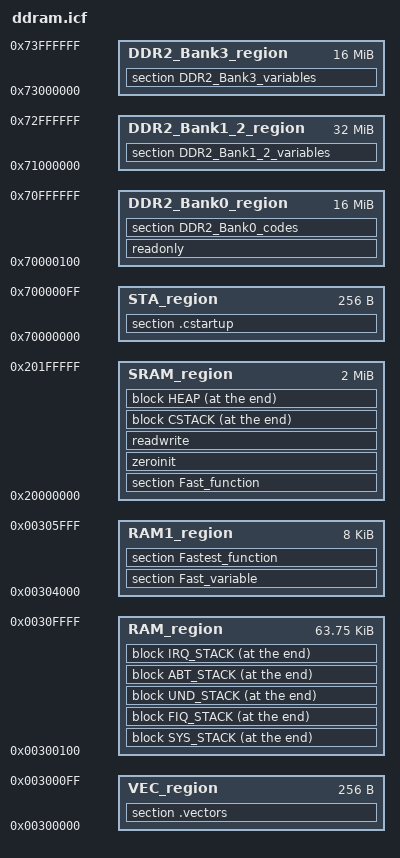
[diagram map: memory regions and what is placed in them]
/*###ICF### Section handled by ICF editor, don't touch! ****/
/*-Editor annotation file-*/
/* IcfEditorFile="$TOOLKIT_DIR$\config\ide\IcfEditor\a_v1_0.xml" */
/*-Memory Regions-*/
define symbol __ICFEDIT_region_SRAM_start__ = 0x20000000;
define symbol __ICFEDIT_region_SRAM_end__   = 0x201FFFFF;

define symbol __ICFEDIT_region_DDR2_Bank0_start__ = 0x70000000;
define symbol __ICFEDIT_region_DDR2_Bank0_end__   = 0x70FFFFFF;
define symbol __ICFEDIT_region_DDR2_Bank1_2_start__ = 0x71000000;
define symbol __ICFEDIT_region_DDR2_Bank1_2_end__   = 0x72FFFFFF;
define symbol __ICFEDIT_region_DDR2_Bank3_start__ = 0x73000000;
define symbol __ICFEDIT_region_DDR2_Bank3_end__   = 0x73FFFFFF;

define symbol __ICFEDIT_region_RAM1_start__   = 0x304000;
define symbol __ICFEDIT_region_RAM1_end__     = 0x305FFF;
define symbol __ICFEDIT_region_IRAM_start__   = 0x300000;
define symbol __ICFEDIT_region_IRAM_end__     = 0x30FFFF;

/*-Sizes-*/
define symbol __ICFEDIT_size_startup__  = 0x100;
define symbol __ICFEDIT_size_vectors__  = 0x100;
define symbol __ICFEDIT_size_cstack__   = 0x2000;
define symbol __ICFEDIT_size_sysstack__ = 0x60;
define symbol __ICFEDIT_size_irqstack__ = 0x60;
define symbol __ICFEDIT_size_fiqstack__ = (3*4);
define symbol __ICFEDIT_size_abtstack__ = (1*4);
define symbol __ICFEDIT_size_undstack__ = (1*4);
define symbol __ICFEDIT_size_heap__     = 0x0;
/*-Exports-*/
export symbol __ICFEDIT_region_SRAM_start__;
export symbol __ICFEDIT_region_DDR2_Bank0_start__;
export symbol __ICFEDIT_region_IRAM_start__;
export symbol __ICFEDIT_region_IRAM_end__;
export symbol __ICFEDIT_size_startup__;
export symbol __ICFEDIT_size_vectors__;
export symbol __ICFEDIT_size_cstack__;
export symbol __ICFEDIT_size_sysstack__;
export symbol __ICFEDIT_size_irqstack__;
export symbol __ICFEDIT_size_fiqstack__;
export symbol __ICFEDIT_size_abtstack__;
export symbol __ICFEDIT_size_undstack__;
export symbol __ICFEDIT_size_heap__;
export symbol __ICFEDIT_region_RAM1_start__;
export symbol __ICFEDIT_region_RAM1_end__;
/**** End of ICF editor section. ###ICF###*/

define memory mem with size = 4G;
define region STA_region =   mem:[from __ICFEDIT_region_DDR2_Bank0_start__  size __ICFEDIT_size_startup__];
define region SRAM_region = mem:[from __ICFEDIT_region_SRAM_start__ to __ICFEDIT_region_SRAM_end__];
define region DDR2_Bank0_region = mem:[from __ICFEDIT_region_DDR2_Bank0_start__+__ICFEDIT_size_startup__ to __ICFEDIT_region_DDR2_Bank0_end__];
define region DDR2_Bank1_2_region = mem:[from __ICFEDIT_region_DDR2_Bank1_2_start__ to __ICFEDIT_region_DDR2_Bank1_2_end__];
define region DDR2_Bank3_region = mem:[from __ICFEDIT_region_DDR2_Bank3_start__ to __ICFEDIT_region_DDR2_Bank3_end__];
define region VEC_region =   mem:[from __ICFEDIT_region_IRAM_start__ size __ICFEDIT_size_vectors__];
define region RAM_region =   mem:[from __ICFEDIT_region_IRAM_start__+__ICFEDIT_size_vectors__ to __ICFEDIT_region_IRAM_end__];
define region RAM1_region =  mem:[from __ICFEDIT_region_RAM1_start__ to __ICFEDIT_region_RAM1_end__];

define block CSTACK    with alignment = 8, size = __ICFEDIT_size_cstack__   { };
define block SYS_STACK with alignment = 8, size = __ICFEDIT_size_sysstack__ { };
define block IRQ_STACK with alignment = 8, size = __ICFEDIT_size_irqstack__ { };
define block FIQ_STACK with alignment = 8, size = __ICFEDIT_size_fiqstack__ { };
define block ABT_STACK with alignment = 8, size = __ICFEDIT_size_abtstack__ { };
define block UND_STACK with alignment = 8, size = __ICFEDIT_size_undstack__ { };
define block HEAP      with alignment = 8, size = __ICFEDIT_size_heap__     { };

initialize by copy with packing = smallest{ section .vectors };
initialize by copy with packing = smallest { readwrite };
initialize by copy with packing = smallest { section Fastest_function };
initialize by copy with packing = smallest { section Fast_function };

do not initialize  { section .noinit };

place in STA_region { section .cstartup };
place in VEC_region { section .vectors };
place at end of RAM_region {block SYS_STACK,block FIQ_STACK, block UND_STACK, block ABT_STACK, block IRQ_STACK};
place in RAM1_region {section Fast_variable, section Fastest_function};
place in SRAM_region {section Fast_function, zeroinit, readwrite};
place at end of SRAM_region {block CSTACK, block HEAP };
place in DDR2_Bank0_region {readonly, section DDR2_Bank0_codes};
place in DDR2_Bank1_2_region {section DDR2_Bank1_2_variables};
place in DDR2_Bank3_region {section DDR2_Bank3_variables};

